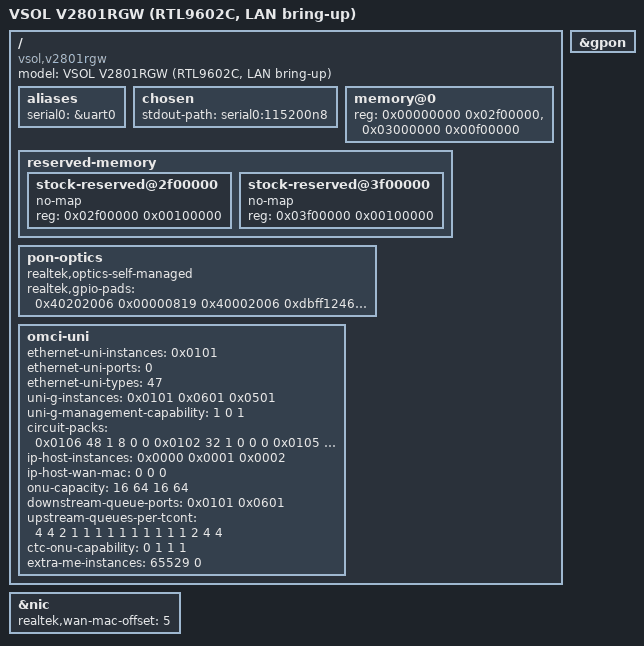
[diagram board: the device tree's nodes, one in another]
// SPDX-License-Identifier: GPL-2.0-or-later
/dts-v1/;

#include "rtl9602c.dtsi"

/ {
	model = "VSOL V2801RGW (RTL9602C, LAN bring-up)";
	compatible = "vsol,v2801rgw", "realtek,rtl9602c";

	aliases {
		serial0 = &uart0;
	};

	chosen {
		stdout-path = "serial0:115200n8";
	};

	memory@0 {
		device_type = "memory";
		reg = <0x00000000 0x02f00000>, <0x03000000 0x00f00000>;
	};

	/* Own stock map and bsp_prom_meminit exclude these; purpose is unproven. */
	reserved-memory {
		#address-cells = <1>;
		#size-cells = <1>;
		ranges;

		stock-reserved@2f00000 {
			no-map;
			reg = <0x02f00000 0x00100000>;
		};

		stock-reserved@3f00000 {
			no-map;
			reg = <0x03f00000 0x00100000>;
		};
	};

	/delete-node/ flash@14000000;
	/delete-node/ watchdog@18003260;

	/* The X111W's pad routing, which this board has run with so far:
	 * IO_GPIO_EN w0 w1, GPIO dir/data ABCD, dir/data EFGH. */
	pon-optics {
		/* MENTECHOPTO NOG22-D6C-ST: its stock kernel carries no host laser
		 * calibration at all (no RTL8290B, no GN25L95 symbol) */
		realtek,optics-self-managed;
		realtek,gpio-pads = <0x40202006 0x00000819 0x40002006 0xdbff1246
				     0x00000819 0x000037e5>;
	};

	/* What the OLT counts, from this board's own stock MIB (stock_gpon_oracle
	 * 2026-10-06, omci_panel.py): one GE UNI, and 30 upstream queues spread
	 * unevenly over 16 T-CONTs. */
	omci-uni {
		ethernet-uni-instances = /bits/ 16 <0x0101>;
		ethernet-uni-ports = /bits/ 8 <0>;
		ethernet-uni-types = /bits/ 8 <47>;
		uni-g-instances = /bits/ 16 <0x0101 0x0601 0x0501>;
		uni-g-management-capability = /bits/ 8 <1 0 1>;
		circuit-packs = /bits/ 16 <
			0x0106  48 1  8  0  0
			0x0102  32 1  0  0  0
			0x0105  40 1  0  0  0
			0x0180 248 1 64 16 16>;
		ip-host-instances = /bits/ 16 <0x0000 0x0001 0x0002>;
		ip-host-wan-mac = /bits/ 8 <0 0 0>;
		onu-capacity = /bits/ 16 <16 64 16 64>;
		downstream-queue-ports = /bits/ 16 <0x0101 0x0601>;
		upstream-queues-per-tcont = /bits/ 8 <4 4 2 1 1 1 1 1 1 1 1 1 1 2 4 4>;
		/* Stock's CTC ONU capability: HGU, TX power supply control 1 (the
		 * core serves 2 undeclared); without it the HSGQ OLT keeps the ISP
		 * ONU type it last saw. */
		ctc-onu-capability = /bits/ 8 <0 1 1 1>;
		extra-me-instances = /bits/ 16 <65529 0>;
	};
};

/* The laser is keyed (operator, 2026-10-03): the module drives it itself
 * (/pon-optics above) and the GTC's burst-enable gates it, active high as
 * stock's "burst-enable polarity: high". */
&gpon {
};

/* Stock's WAN MAC is LAN+5: the OLT learnt 80:14:a8:87:d0:2d behind this
 * unit's row while stock ran (2026-09-30). */
&nic {
	realtek,wan-mac-offset = <5>;
};
